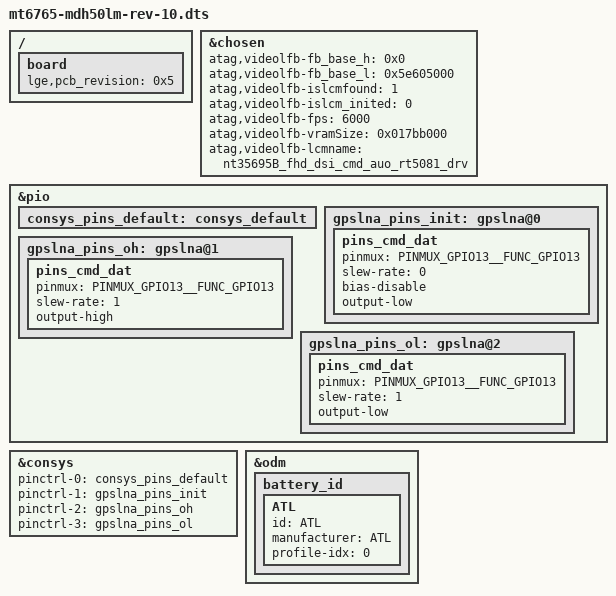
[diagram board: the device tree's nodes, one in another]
/*
 * Copyright (C) 2019 MediaTek Inc.
 *
 * This program is free software; you can redistribute it and/or modify
 * it under the terms of the GNU General Public License version 2 as
 * published by the Free Software Foundation.
 *
 * This program is distributed in the hope that it will be useful,
 * but WITHOUT ANY WARRANTY; without even the implied warranty of
 * MERCHANTABILITY or FITNESS FOR A PARTICULAR PURPOSE.
 * See http://www.gnu.org/licenses/gpl-2.0.html for more details.
 */
#include <dt-bindings/interrupt-controller/arm-gic.h>
#include <dt-bindings/interrupt-controller/irq.h>
#include <dt-bindings/pinctrl/mt6765-pinfunc.h>
#include <dt-bindings/clock/mt6765-clk.h>

/dts-v1/;
/plugin/;

#include "mt6765-mdh50lm-camera.dtsi"
#include "mt6765-mdh50lm-common.dtsi"
#include "mt6765-mdh50lm-fingerprint.dtsi"
#include "mt6765-mdh50lm-misc.dtsi"
#include "mt6765-mdh50lm-nfc.dtsi"
#include "mt6765-mdh50lm-panel.dtsi"
#include "mt6765-mdh50lm-power.dtsi"
#include "mt6765-mdh50lm-sensor.dtsi"
#include "mt6765-mdh50lm-sound.dtsi"
#include "mt6765-mdh50lm-touch.dtsi"
#include "mt6765-mdh50lm-usb.dtsi"
/*#include "mt6765-mdh50lm-mme.dtsi"*/
#include "mt6765-mdh50lm-cust-rev10.dtsi"

/{
       board {
               /*
                  typedef enum {
                  HW_REV_0 = 0,
                  HW_REV_0_1,
                  HW_REV_A,
                  HW_REV_B,
                  HW_REV_C,
                  HW_REV_1_0,
                  HW_REV_1_1,
                  HW_REV_MAX
                  } rev_type;
                */
               lge,pcb_revision = <0x5>; // rev_10
       };
};

/* chosen */
&chosen {

	/* fpga may has no lk, we need to specify display info here */
	/* fb buffer is reserved using this dts by memory node above */
	atag,videolfb-fb_base_h = <0x0>;
	atag,videolfb-fb_base_l = <0x5e605000>;
	atag,videolfb-islcmfound = <1>;
	/* because no lk, so lcm is not inited */
	atag,videolfb-islcm_inited = <0>;
	atag,videolfb-fps= <6000>;
	atag,videolfb-vramSize= <0x017bb000>;
	atag,videolfb-lcmname= "nt35695B_fhd_dsi_cmd_auo_rt5081_drv";
};
/*
&i2c3 {
	ext_buck_lp4@57 {
		regulator-name ="ext_buck_vdd2";
		regulator-min-microvolt = <300000>;
		regulator-max-microvolt = <1300000>;
		vsel_pin = <0>;
	};

	ext_buck_lp4x@50 {
		regulator-name ="ext_buck_vddq";
		regulator-min-microvolt = <300000>;
		regulator-max-microvolt = <1300000>;
		vsel_pin = <1>;
	};
};

&i2c6 {
	ext_buck_vgpu@55 {
		regulator-name ="ext_buck_vgpu";
		regulator-min-microvolt = <300000>;
		regulator-max-microvolt = <1300000>;
		vsel_pin = <2>;
	};
};
*/

/* CONSYS GPIO standardization */
&pio {
	consys_pins_default: consys_default {
	};
	gpslna_pins_init: gpslna@0 {
		pins_cmd_dat {
			pinmux = <PINMUX_GPIO13__FUNC_GPIO13>;
			slew-rate = <0>;
			bias-disable;
			output-low;
		};
	};
	gpslna_pins_oh: gpslna@1 {
		pins_cmd_dat {
			pinmux = <PINMUX_GPIO13__FUNC_GPIO13>;
			slew-rate = <1>;
			output-high;
		};
	};
	gpslna_pins_ol: gpslna@2 {
		pins_cmd_dat {
			pinmux = <PINMUX_GPIO13__FUNC_GPIO13>;
			slew-rate = <1>;
			output-low;
		};
	};
};
&consys {
	pinctrl-names = "default", "gps_lna_state_init",
		"gps_lna_state_oh", "gps_lna_state_ol";
	pinctrl-0 = <&consys_pins_default>;
	pinctrl-1 = <&gpslna_pins_init>;
	pinctrl-2 = <&gpslna_pins_oh>;
	pinctrl-3 = <&gpslna_pins_ol>;
	status = "okay";
};
/* CONSYS end */

/* IRTX GPIO end */
/*
&irtx_pwm {
	pinctrl-names = "irtx_gpio_led_default", "irtx_gpio_led_set";
	pinctrl-0 = <&irtx_gpio_led_default>;
	pinctrl-1 = <&irtx_gpio_led_set>;
	status = "okay";
};
&pio {
	irtx_gpio_led_default:irtx_gpio_led_def@gpio90 {
		pins_cmd_dat {
			pinmux = <PINMUX_GPIO90__FUNC_GPIO90>;
			slew-rate = <1>;
			bias-disable;
			output-low;
			input-schmitt-enable = <0>;
		};
	};

	irtx_gpio_led_set:irtx_gpio_led_set@gpio90 {
		pins_cmd_dat {
			pinmux = <PINMUX_GPIO90__FUNC_PWM0>;
			slew-rate = <1>;
			output-high;
		};
	};
};
*/
/* IRTX GPIO Settings -End */

&odm {
	battery_id {
		/* Support ATL(DUMMY Battery R 120K)*/
		ATL {
			id = "ATL";
			manufacturer = "ATL";
			profile-idx = <0>;
		};
	};
};

/* #include <muse6765_dh50_q/cust.dtsi> */
/* #include "cust_mt6765_camera.dtsi" */
/*End of this file, DO NOT ADD ANYTHING HERE*/
